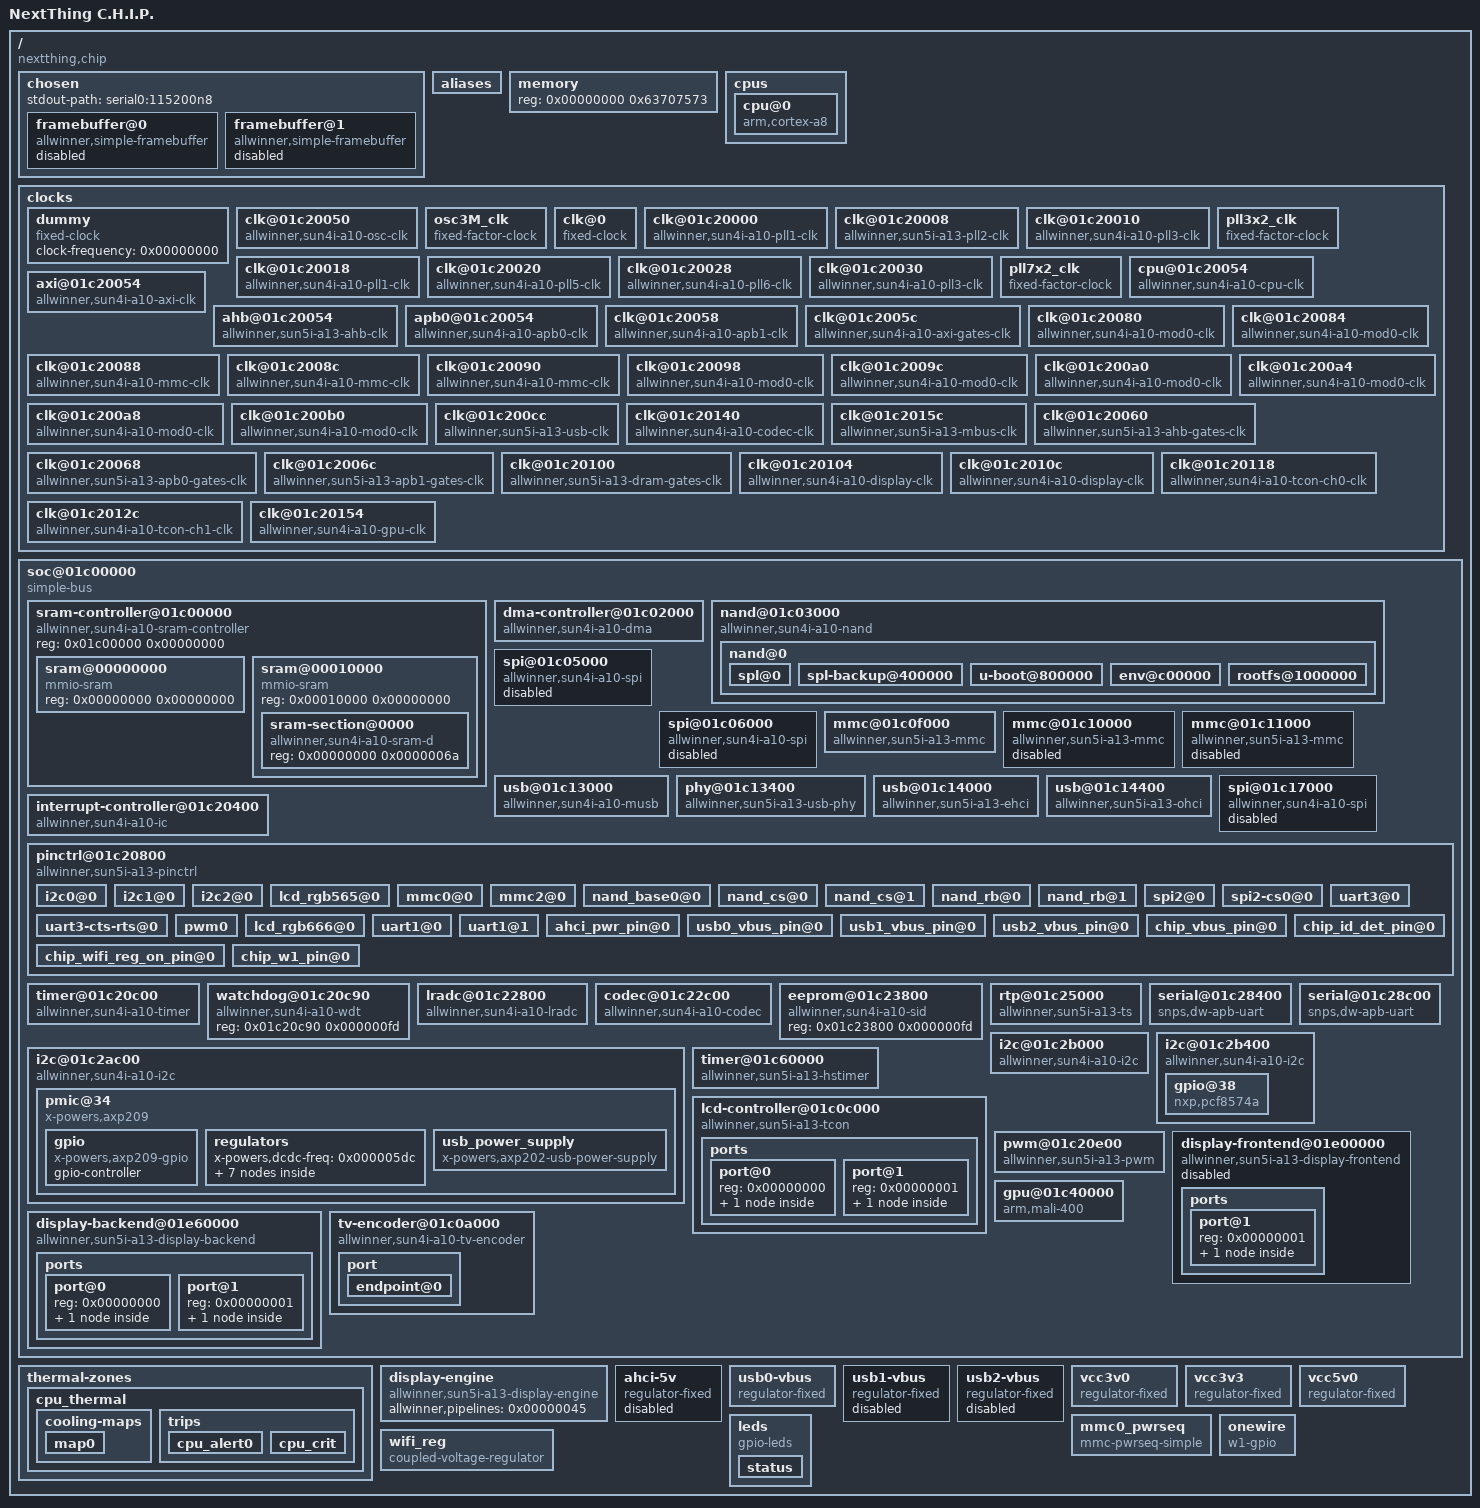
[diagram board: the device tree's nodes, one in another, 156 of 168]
/dts-v1/;
// magic:		0xd00dfeed
// totalsize:		0x9e24 (40484)
// off_dt_struct:	0x38
// off_dt_strings:	0x9414
// off_mem_rsvmap:	0x28
// version:		17
// last_comp_version:	16
// boot_cpuid_phys:	0x0
// size_dt_strings:	0xa10
// size_dt_struct:	0x93dc

/ {
    #address-cells = <0x00000001>;
    #size-cells = <0x00000001>;
    interrupt-parent = <0x00000001>;
    model = "NextThing C.H.I.P.";
    compatible = "nextthing,chip", "allwinner,sun5i-r8", "allwinner,sun5i-a13";
    chosen {
        #address-cells = <0x00000001>;
        #size-cells = <0x00000001>;
        ranges;
        stdout-path = "serial0:115200n8";
        framebuffer@0 {
            compatible = "allwinner,simple-framebuffer", "simple-framebuffer";
            allwinner,pipeline = "de_be0-lcd0";
            clocks = <0x00000002 0x00000003 0x00000003 0x626c6564 0x6672616d 0x00000003 0x696e6e65 0x6d656275>;
            status = "disabled";
        };
        framebuffer@1 {
            compatible = "allwinner,simple-framebuffer", "simple-framebuffer";
            allwinner,pipeline = "de_be0-lcd0-tve0";
            clocks = <0x00000002 0x00000002 0x00000005 0x0000006a 0x00000002 0x73657300 0x2f736f63 0x63403031 0x0000001b 0x30303030>;
            status = "disabled";
        };
    };
    aliases {
        i2c0 = "/soc@01c00000/i2c@01c2ac00";
        i2c1 = "/soc@01c00000/i2c@01c2b000";
        i2c2 = "/soc@01c00000/i2c@01c2b400";
        serial0 = "/soc@01c00000/serial@01c28400";
        serial1 = "/soc@01c00000/serial@01c28c00";
    };
    memory {
        device_type = "memory";
        reg = <0x00000000 0x63707573>;
    };
    cpus {
        #address-cells = <0x00000001>;
        #size-cells = <0x00000000>;
        cpu@0 {
            device_type = "cpu";
            compatible = "arm,cortex-a8";
            reg = <0x00000000>;
            clocks = <0x00000007>;
            clock-latency = <0x0003b9b0>;
            operating-points = <0x000f6180 0x000d2f00 0x0008ca00 0x00000003 0x00000003 0x00000003 0x00000003 0x00000003 0x00000003 0x00000002 0x6b730000 0x00000001>;
            #cooling-cells = <0x00000002>;
            cooling-min-level = <0x00000000>;
            cooling-max-level = <0x00000005>;
            cpu-supply = <0x00000008>;
            linux,phandle = <0x00000044>;
            phandle = <0x00000044>;
        };
    };
    clocks {
        #address-cells = <0x00000001>;
        #size-cells = <0x00000001>;
        ranges;
        dummy {
            #clock-cells = <0x00000000>;
            compatible = "fixed-clock";
            clock-frequency = <0x00000000>;
            linux,phandle = <0x0000000f>;
            phandle = <0x0000000f>;
        };
        clk@01c20050 {
            #clock-cells = <0x00000000>;
            compatible = "allwinner,sun4i-a10-osc-clk";
            reg = <0x01c20050 0x00000118>;
            clock-frequency = <0x016e3600>;
            clock-output-names = "osc24M";
            linux,phandle = <0x00000009>;
            phandle = <0x00000009>;
        };
        osc3M_clk {
            compatible = "fixed-factor-clock";
            #clock-cells = <0x00000000>;
            clock-div = <0x00000008>;
            clock-mult = <0x00000001>;
            clocks = <0x00000009>;
            clock-output-names = "osc3M";
            linux,phandle = <0x0000000a>;
            phandle = <0x0000000a>;
        };
        clk@0 {
            #clock-cells = <0x00000000>;
            compatible = "fixed-clock";
            clock-frequency = <0x00008000>;
            clock-output-names = "osc32k";
            linux,phandle = <0x0000000d>;
            phandle = <0x0000000d>;
        };
        clk@01c20000 {
            #clock-cells = <0x00000000>;
            compatible = "allwinner,sun4i-a10-pll1-clk";
            reg = <0x01c20000 0x00000063>;
            clocks = <0x00000009>;
            clock-output-names = "pll1";
            linux,phandle = <0x0000000e>;
            phandle = <0x0000000e>;
        };
        clk@01c20008 {
            #clock-cells = <0x00000001>;
            compatible = "allwinner,sun5i-a13-pll2-clk";
            reg = <0x01c20008 0x00000063>;
            clocks = <0x00000009>;
            clock-output-names = "pll2-1x", "pll2-2x", "pll2-4x", "pll2-8x";
            linux,phandle = <0x00000014>;
            phandle = <0x00000014>;
        };
        clk@01c20010 {
            #clock-cells = <0x00000000>;
            compatible = "allwinner,sun4i-a10-pll3-clk";
            reg = <0x01c20010 0x00000063>;
            clocks = <0x0000000a>;
            clock-output-names = "pll3";
            linux,phandle = <0x0000000b>;
            phandle = <0x0000000b>;
        };
        pll3x2_clk {
            compatible = "fixed-factor-clock";
            #clock-cells = <0x00000000>;
            clock-div = <0x00000001>;
            clock-mult = <0x00000002>;
            clocks = <0x0000000b>;
            clock-output-names = "pll3-2x";
            linux,phandle = <0x00000017>;
            phandle = <0x00000017>;
        };
        clk@01c20018 {
            #clock-cells = <0x00000000>;
            compatible = "allwinner,sun4i-a10-pll1-clk";
            reg = <0x01c20018 0x00000063>;
            clocks = <0x00000009>;
            clock-output-names = "pll4";
            linux,phandle = <0x00000019>;
            phandle = <0x00000019>;
        };
        clk@01c20020 {
            #clock-cells = <0x00000001>;
            compatible = "allwinner,sun4i-a10-pll5-clk";
            reg = <0x01c20020 0x00000063>;
            clocks = <0x00000009>;
            clock-output-names = "pll5_ddr", "pll5_other";
            linux,phandle = <0x00000013>;
            phandle = <0x00000013>;
        };
        clk@01c20028 {
            #clock-cells = <0x00000001>;
            compatible = "allwinner,sun4i-a10-pll6-clk";
            reg = <0x01c20028 0x00000063>;
            clocks = <0x00000009>;
            clock-output-names = "pll6_sata", "pll6_other", "pll6";
            linux,phandle = <0x00000011>;
            phandle = <0x00000011>;
        };
        clk@01c20030 {
            #clock-cells = <0x00000000>;
            compatible = "allwinner,sun4i-a10-pll3-clk";
            reg = <0x01c20030 0x00000063>;
            clocks = <0x0000000a>;
            clock-output-names = "pll7";
            linux,phandle = <0x0000000c>;
            phandle = <0x0000000c>;
        };
        pll7x2_clk {
            compatible = "fixed-factor-clock";
            #clock-cells = <0x00000000>;
            clock-div = <0x00000001>;
            clock-mult = <0x00000002>;
            clocks = <0x0000000c>;
            clock-output-names = "pll7-2x";
            linux,phandle = <0x00000018>;
            phandle = <0x00000018>;
        };
        cpu@01c20054 {
            #clock-cells = <0x00000000>;
            compatible = "allwinner,sun4i-a10-cpu-clk";
            reg = <0x01c20054 0x00000063>;
            clocks = <0x0000000d 0x00000003 0x00000003 0x00000003>;
            clock-output-names = "cpu";
            linux,phandle = <0x00000007>;
            phandle = <0x00000007>;
        };
        axi@01c20054 {
            #clock-cells = <0x00000000>;
            compatible = "allwinner,sun4i-a10-axi-clk";
            reg = <0x01c20054 0x00000063>;
            clocks = <0x00000007>;
            clock-output-names = "axi";
            linux,phandle = <0x00000010>;
            phandle = <0x00000010>;
        };
        ahb@01c20054 {
            #clock-cells = <0x00000000>;
            compatible = "allwinner,sun5i-a13-ahb-clk";
            reg = <0x01c20054 0x00000063>;
            clocks = <0x00000010 0x00000003 0x00000003 0x00000003>;
            clock-output-names = "ahb";
            assigned-clocks = <0x00000012>;
            assigned-clock-parents = <0x00000011 0x000000fd>;
            linux,phandle = <0x00000012>;
            phandle = <0x00000012>;
        };
        apb0@01c20054 {
            #clock-cells = <0x00000000>;
            compatible = "allwinner,sun4i-a10-apb0-clk";
            reg = <0x01c20054 0x00000063>;
            clocks = <0x00000012>;
            clock-output-names = "apb0";
            linux,phandle = <0x00000015>;
            phandle = <0x00000015>;
        };
        clk@01c20058 {
            #clock-cells = <0x00000000>;
            compatible = "allwinner,sun4i-a10-apb1-clk";
            reg = <0x01c20058 0x00000063>;
            clocks = <0x00000009 0x00000003 0x00000000 0x00000016>;
            clock-output-names = "apb1";
            linux,phandle = <0x00000016>;
            phandle = <0x00000016>;
        };
        clk@01c2005c {
            #clock-cells = <0x00000001>;
            compatible = "allwinner,sun4i-a10-axi-gates-clk";
            reg = <0x01c2005c 0x00000063>;
            clocks = <0x00000010>;
            clock-indices = <0x00000000>;
            clock-output-names = "axi_dram";
            linux,phandle = <0x0000004f>;
            phandle = <0x0000004f>;
        };
        clk@01c20080 {
            #clock-cells = <0x00000000>;
            compatible = "allwinner,sun4i-a10-mod0-clk";
            reg = <0x01c20080 0x00000063>;
            clocks = <0x00000009 0x00000001 0x6e616e64 0x000000fd 0x00000103>;
            clock-output-names = "nand";
            linux,phandle = <0x0000001a>;
            phandle = <0x0000001a>;
        };
        clk@01c20084 {
            #clock-cells = <0x00000000>;
            compatible = "allwinner,sun4i-a10-mod0-clk";
            reg = <0x01c20084 0x00000063>;
            clocks = <0x00000009 0x00000001 0x6d730000 0x00000050 0x00000050>;
            clock-output-names = "ms";
            linux,phandle = <0x00000050>;
            phandle = <0x00000050>;
        };
        clk@01c20088 {
            #clock-cells = <0x00000001>;
            compatible = "allwinner,sun4i-a10-mmc-clk";
            reg = <0x01c20088 0x00000063>;
            clocks = <0x00000009 0x00000001 0x6d6d6330 0x006d6d63 0x00000003>;
            clock-output-names = "mmc0", "mmc0_output", "mmc0_sample";
            linux,phandle = <0x00000021>;
            phandle = <0x00000021>;
        };
        clk@01c2008c {
            #clock-cells = <0x00000001>;
            compatible = "allwinner,sun4i-a10-mmc-clk";
            reg = <0x01c2008c 0x00000063>;
            clocks = <0x00000009 0x00000001 0x6d6d6331 0x006d6d63 0x00000003>;
            clock-output-names = "mmc1", "mmc1_output", "mmc1_sample";
            linux,phandle = <0x00000025>;
            phandle = <0x00000025>;
        };
        clk@01c20090 {
            #clock-cells = <0x00000001>;
            compatible = "allwinner,sun4i-a10-mmc-clk";
            reg = <0x01c20090 0x00000063>;
            clocks = <0x00000009 0x00000001 0x6d6d6332 0x006d6d63 0x00000003>;
            clock-output-names = "mmc2", "mmc2_output", "mmc2_sample";
            linux,phandle = <0x00000026>;
            phandle = <0x00000026>;
        };
        clk@01c20098 {
            #clock-cells = <0x00000000>;
            compatible = "allwinner,sun4i-a10-mod0-clk";
            reg = <0x01c20098 0x00000063>;
            clocks = <0x00000009 0x00000001 0x74730000 0x00000051 0x00000051>;
            clock-output-names = "ts";
            linux,phandle = <0x00000051>;
            phandle = <0x00000051>;
        };
        clk@01c2009c {
            #clock-cells = <0x00000000>;
            compatible = "allwinner,sun4i-a10-mod0-clk";
            reg = <0x01c2009c 0x00000063>;
            clocks = <0x00000009 0x00000001 0x73730000 0x00000052 0x00000052>;
            clock-output-names = "ss";
            linux,phandle = <0x00000052>;
            phandle = <0x00000052>;
        };
        clk@01c200a0 {
            #clock-cells = <0x00000000>;
            compatible = "allwinner,sun4i-a10-mod0-clk";
            reg = <0x01c200a0 0x00000063>;
            clocks = <0x00000009 0x00000001 0x73706930 0x000000fd 0x00000103>;
            clock-output-names = "spi0";
            linux,phandle = <0x0000001f>;
            phandle = <0x0000001f>;
        };
        clk@01c200a4 {
            #clock-cells = <0x00000000>;
            compatible = "allwinner,sun4i-a10-mod0-clk";
            reg = <0x01c200a4 0x00000063>;
            clocks = <0x00000009 0x00000001 0x73706931 0x000000fd 0x00000103>;
            clock-output-names = "spi1";
            linux,phandle = <0x00000020>;
            phandle = <0x00000020>;
        };
        clk@01c200a8 {
            #clock-cells = <0x00000000>;
            compatible = "allwinner,sun4i-a10-mod0-clk";
            reg = <0x01c200a8 0x00000063>;
            clocks = <0x00000009 0x00000001 0x73706932 0x000000fd 0x00000103>;
            clock-output-names = "spi2";
            linux,phandle = <0x0000002f>;
            phandle = <0x0000002f>;
        };
        clk@01c200b0 {
            #clock-cells = <0x00000000>;
            compatible = "allwinner,sun4i-a10-mod0-clk";
            reg = <0x01c200b0 0x00000063>;
            clocks = <0x00000009 0x00000001 0x69723000 0x00000053 0x00000053>;
            clock-output-names = "ir0";
            linux,phandle = <0x00000053>;
            phandle = <0x00000053>;
        };
        clk@01c200cc {
            #clock-cells = <0x00000001>;
            #reset-cells = <0x00000001>;
            compatible = "allwinner,sun5i-a13-usb-clk";
            reg = <0x01c200cc 0x00000063>;
            clocks = <0x00000011 0x00000128>;
            clock-output-names = "usb_ohci0", "usb_phy";
            linux,phandle = <0x00000029>;
            phandle = <0x00000029>;
        };
        clk@01c20140 {
            #clock-cells = <0x00000000>;
            compatible = "allwinner,sun4i-a10-codec-clk";
            reg = <0x01c20140 0x00000063>;
            clocks = <0x00000014 0x00000128>;
            clock-output-names = "codec";
            linux,phandle = <0x00000032>;
            phandle = <0x00000032>;
        };
        clk@01c2015c {
            #clock-cells = <0x00000000>;
            compatible = "allwinner,sun5i-a13-mbus-clk";
            reg = <0x01c2015c 0x00000063>;
            clocks = <0x00000009 0x00000001 0x6d627573 0x000000fd 0x00000103>;
            clock-output-names = "mbus";
            linux,phandle = <0x00000054>;
            phandle = <0x00000054>;
        };
        clk@01c20060 {
            #clock-cells = <0x00000001>;
            compatible = "allwinner,sun5i-a13-ahb-gates-clk";
            reg = <0x01c20060 0x00000063>;
            clocks = <0x00000012>;
            clock-indices = <0x00000000 0x00000006 0x0000000a 0x00000015 0x00000022 0x0000002e 0x000000d0 0x74670061 0x6f686369 0x646d6100 0x5f6d6d63 0x68625f6d 0x00616862 0x70693000 0x5f737069 0x00616862 0x6168625f 0x6168625f 0x5f666500 0x6d616c69 0x000000fd 0x00000103 0x636c6b40>;
            clock-output-names = "ahb_usbotg", "ahb_ehci", "ahb_ohci", "ahb_ss", "ahb_dma", "ahb_bist", "ahb_mmc0", "ahb_mmc1", "ahb_mmc2", "ahb_nand", "ahb_sdram", "ahb_spi0", "ahb_spi1", "ahb_spi2", "ahb_stimer", "ahb_ve", "ahb_tve", "ahb_lcd", "ahb_csi", "ahb_de_be", "ahb_de_fe", "ahb_iep", "ahb_mali400";
            linux,phandle = <0x00000002>;
            phandle = <0x00000002>;
        };
        clk@01c20068 {
            #clock-cells = <0x00000001>;
            compatible = "allwinner,sun5i-a13-apb0-gates-clk";
            reg = <0x01c20068 0x00000063>;
            clocks = <0x00000015>;
            clock-indices = <0x00000000 0x0000001c 0x65630061>;
            clock-output-names = "apb0_codec", "apb0_pio", "apb0_ir";
            linux,phandle = <0x00000030>;
            phandle = <0x00000030>;
        };
        clk@01c2006c {
            #clock-cells = <0x00000001>;
            compatible = "allwinner,sun5i-a13-apb1-gates-clk";
            reg = <0x01c2006c 0x00000063>;
            clocks = <0x00000016>;
            clock-indices = <0x00000000 0x00000013 0x61706231 0x32633100 0x62315f75>;
            clock-output-names = "apb1_i2c0", "apb1_i2c1", "apb1_i2c2", "apb1_uart1", "apb1_uart3";
            linux,phandle = <0x00000033>;
            phandle = <0x00000033>;
        };
        clk@01c20100 {
            #clock-cells = <0x00000001>;
            compatible = "allwinner,sun5i-a13-dram-gates-clk", "allwinner,sun4i-a10-gates-clk";
            reg = <0x01c20100 0x00000063>;
            clocks = <0x00000013 0x00000177>;
            clock-indices = <0x00000000 0x0000001d 0x00000128 0x5f637369 0x6472616d 0x61636500>;
            clock-output-names = "dram_ve", "dram_csi", "dram_de_fe", "dram_de_be", "dram_ace", "dram_iep";
            linux,phandle = <0x00000005>;
            phandle = <0x00000005>;
        };
        clk@01c20104 {
            #clock-cells = <0x00000000>;
            #reset-cells = <0x00000000>;
            compatible = "allwinner,sun4i-a10-display-clk";
            reg = <0x01c20104 0x00000063>;
            clocks = <0x0000000b 0x00000003 0x65000000 0x00000003>;
            clock-output-names = "de-be";
            linux,phandle = <0x00000003>;
            phandle = <0x00000003>;
        };
        clk@01c2010c {
            #clock-cells = <0x00000000>;
            #reset-cells = <0x00000000>;
            compatible = "allwinner,sun4i-a10-display-clk";
            reg = <0x01c2010c 0x00000063>;
            clocks = <0x0000000b 0x00000003 0x65000000 0x0000003c>;
            clock-output-names = "de-fe";
            linux,phandle = <0x0000003c>;
            phandle = <0x0000003c>;
        };
        clk@01c20118 {
            #clock-cells = <0x00000000>;
            #reset-cells = <0x00000001>;
            compatible = "allwinner,sun4i-a10-tcon-ch0-clk";
            reg = <0x01c20118 0x00000063>;
            clocks = <0x0000000b 0x00000003 0x2d636830 0x00000004>;
            clock-output-names = "tcon-ch0-sclk";
            linux,phandle = <0x00000004>;
            phandle = <0x00000004>;
        };
        clk@01c2012c {
            #clock-cells = <0x00000000>;
            compatible = "allwinner,sun4i-a10-tcon-ch1-clk";
            reg = <0x01c2012c 0x00000063>;
            clocks = <0x0000000b 0x00000003 0x2d636831 0x00000004>;
            clock-output-names = "tcon-ch1-sclk";
            linux,phandle = <0x00000006>;
            phandle = <0x00000006>;
        };
        clk@01c20154 {
            #clock-cells = <0x00000000>;
            #reset-cells = <0x00000000>;
            compatible = "allwinner,sun4i-a10-gpu-clk";
            reg = <0x01c20154 0x00000063>;
            clocks = <0x0000000b 0x0000000c 0x00000128 0x00000004 0x00000004 0x00000002>;
            clock-output-names = "mali";
            linux,phandle = <0x00000041>;
            phandle = <0x00000041>;
        };
    };
    soc@01c00000 {
        compatible = "simple-bus";
        #address-cells = <0x00000001>;
        #size-cells = <0x00000001>;
        ranges;
        sram-controller@01c00000 {
            compatible = "allwinner,sun4i-a10-sram-controller";
            reg = <0x01c00000 0x00000000>;
            #address-cells = <0x00000001>;
            #size-cells = <0x00000001>;
            ranges;
            sram@00000000 {
                compatible = "mmio-sram";
                reg = <0x00000000 0x00000000>;
                #address-cells = <0x00000001>;
                #size-cells = <0x00000001>;
                ranges = <0x00000000 0x00000004 0x00000004>;
                linux,phandle = <0x00000055>;
                phandle = <0x00000055>;
            };
            sram@00010000 {
                compatible = "mmio-sram";
                reg = <0x00010000 0x00000000>;
                #address-cells = <0x00000001>;
                #size-cells = <0x00000001>;
                ranges = <0x00000000 0x00000004 0x00000004>;
                linux,phandle = <0x00000056>;
                phandle = <0x00000056>;
                sram-section@0000 {
                    compatible = "allwinner,sun4i-a10-sram-d";
                    reg = <0x00000000 0x0000006a>;
                    status = "okay";
                    linux,phandle = <0x00000028>;
                    phandle = <0x00000028>;
                };
            };
        };
        dma-controller@01c02000 {
            compatible = "allwinner,sun4i-a10-dma";
            reg = <0x01c02000 0x00000192>;
            interrupts = <0x0000001b>;
            clocks = <0x00000002 0x0000019d>;
            #dma-cells = <0x00000002>;
            linux,phandle = <0x0000001e>;
            phandle = <0x0000001e>;
        };
        nand@01c03000 {
            compatible = "allwinner,sun4i-a10-nand";
            reg = <0x01c03000 0x00000192>;
            interrupts = <0x00000025>;
            clocks = <0x00000002 0x00000008 0x00000003>;
            clock-names = "ahb", "mod";
            #address-cells = <0x00000001>;
            #size-cells = <0x00000000>;
            status = "okay";
            pinctrl-names = "default";
            pinctrl-0 = <0x0000001b 0x0000000c 0x00000003>;
            dmas = <0x0000001e 0x00000005 0x00000003>;
            dma-names = "rxtx";
            linux,phandle = <0x00000057>;
            phandle = <0x00000057>;
            nand@0 {
                #address-cells = <0x00000002>;
                #size-cells = <0x00000002>;
                reg = <0x00000000>;
                allwinner,rb = <0x00000000>;
                nand-ecc-mode = "hw";
                spl@0 {
                    label = "SPL";
                    reg = <0x00000000 0x00000002 0x75704034 0x0000000b>;
                };
                spl-backup@400000 {
                    label = "SPL.backup";
                    reg = <0x00000000 0x00000002 0x30303030 0x000001f6>;
                };
                u-boot@800000 {
                    label = "U-Boot";
                    reg = <0x00000000 0x00000002 0x30300000 0x656e7600>;
                };
                env@c00000 {
                    label = "env";
                    reg = <0x00000000 0x00000002 0x30303030 0x000001f6>;
                };
                rootfs@1000000 {
                    label = "rootfs";
                    reg = <0x00000000 0x00000002 0x73706940 0x00000003>;
                };
            };
        };
        spi@01c05000 {
            compatible = "allwinner,sun4i-a10-spi";
            reg = <0x01c05000 0x00000192>;
            interrupts = <0x0000000a>;
            clocks = <0x00000002 0x00000008 0x00000003>;
            clock-names = "ahb", "mod";
            dmas = <0x0000001e 0x00000001 0x000001d1 0x00000009 0x00000000 0x00000001>;
            dma-names = "rx", "tx";
            status = "disabled";
            #address-cells = <0x00000001>;
            #size-cells = <0x00000000>;
            linux,phandle = <0x00000058>;
            phandle = <0x00000058>;
        };
        spi@01c06000 {
            compatible = "allwinner,sun4i-a10-spi";
            reg = <0x01c06000 0x00000192>;
            interrupts = <0x0000000b>;
            clocks = <0x00000002 0x00000008 0x00000003>;
            clock-names = "ahb", "mod";
            dmas = <0x0000001e 0x00000001 0x000001d1 0x00000009 0x00000000 0x00000001>;
            dma-names = "rx", "tx";
            status = "disabled";
            #address-cells = <0x00000001>;
            #size-cells = <0x00000000>;
            linux,phandle = <0x00000059>;
            phandle = <0x00000059>;
        };
        mmc@01c0f000 {
            compatible = "allwinner,sun5i-a13-mmc";
            reg = <0x01c0f000 0x00000063>;
            clocks = <0x00000002 0x00000021 0x00000003 0x6d6d6300 0x65000000 0x00000020 0x6f6b6179 0x00000000>;
            clock-names = "ahb", "mmc", "output", "sample";
            interrupts = <0x00000020>;
            status = "okay";
            #address-cells = <0x00000001>;
            #size-cells = <0x00000000>;
            pinctrl-names = "default";
            pinctrl-0 = <0x00000022>;
            vmmc-supply = <0x00000023>;
            mmc-pwrseq = <0x00000024>;
            bus-width = <0x00000004>;
            non-removable;
            linux,phandle = <0x0000005a>;
            phandle = <0x0000005a>;
        };
        mmc@01c10000 {
            compatible = "allwinner,sun5i-a13-mmc";
            reg = <0x01c10000 0x00000063>;
            clocks = <0x00000002 0x00000025 0x00000003 0x6d6d6300 0x65000000 0x00000021 0x64697361 0x00000004>;
            clock-names = "ahb", "mmc", "output", "sample";
            interrupts = <0x00000021>;
            status = "disabled";
            #address-cells = <0x00000001>;
            #size-cells = <0x00000000>;
            linux,phandle = <0x0000005b>;
            phandle = <0x0000005b>;
        };
        mmc@01c11000 {
            compatible = "allwinner,sun5i-a13-mmc";
            reg = <0x01c11000 0x00000063>;
            clocks = <0x00000002 0x00000026 0x00000003 0x6d6d6300 0x65000000 0x00000022 0x64697361 0x00000004>;
            clock-names = "ahb", "mmc", "output", "sample";
            interrupts = <0x00000022>;
            status = "disabled";
            #address-cells = <0x00000001>;
            #size-cells = <0x00000000>;
            linux,phandle = <0x0000005c>;
            phandle = <0x0000005c>;
        };
        usb@01c13000 {
            compatible = "allwinner,sun4i-a10-musb";
            reg = <0x01c13000 0x00000063>;
            clocks = <0x00000002 0x00000192>;
            interrupts = <0x00000026>;
            interrupt-names = "mc";
            phys = <0x00000027 0x00000240>;
            phy-names = "usb";
            extcon = <0x00000027 0x00000251>;
            allwinner,sram = <0x00000028 0x0000006a>;
            status = "okay";
            dr_mode = "otg";
            linux,phandle = <0x0000005d>;
            phandle = <0x0000005d>;
        };
        phy@01c13400 {
            #phy-cells = <0x00000001>;
            compatible = "allwinner,sun5i-a13-usb-phy";
            reg = <0x01c13400 0x00000003 0x6374726c 0x00000008>;
            reg-names = "phy_ctrl", "pmu1";
            clocks = <0x00000029 0x000001a8>;
            clock-names = "usb_phy";
            resets = <0x00000029 0x00000003 0x5f726573 0x74000000>;
            reset-names = "usb0_reset", "usb1_reset";
            status = "okay";
            pinctrl-names = "default";
            pinctrl-0 = <0x0000002a>;
            usb0_id_det-gpio = <0x0000002b 0x00000003 0x00000003 0x00000003>;
            usb0_vbus_power-supply = <0x0000002c>;
            usb0_vbus-supply = <0x0000002d>;
            usb1_vbus-supply = <0x0000002e>;
            linux,phandle = <0x00000027>;
            phandle = <0x00000027>;
        };
        usb@01c14000 {
            compatible = "allwinner,sun5i-a13-ehci", "generic-ehci";
            reg = <0x01c14000 0x00000192>;
            interrupts = <0x00000027>;
            clocks = <0x00000002 0x0000023b>;
            phys = <0x00000027 0x00000240>;
            phy-names = "usb";
            status = "okay";
            linux,phandle = <0x0000005e>;
            phandle = <0x0000005e>;
        };
        usb@01c14400 {
            compatible = "allwinner,sun5i-a13-ohci", "generic-ohci";
            reg = <0x01c14400 0x00000192>;
            interrupts = <0x00000028>;
            clocks = <0x00000029 0x00000003 0x00000001 0x75736200>;
            phys = <0x00000027 0x00000240>;
            phy-names = "usb";
            status = "okay";
            linux,phandle = <0x0000005f>;
            phandle = <0x0000005f>;
        };
        spi@01c17000 {
            compatible = "allwinner,sun4i-a10-spi";
            reg = <0x01c17000 0x00000192>;
            interrupts = <0x0000000c>;
            clocks = <0x00000002 0x00000008 0x00000003>;
            clock-names = "ahb", "mod";
            dmas = <0x0000001e 0x00000001 0x000001d1 0x00000009 0x00000000 0x00000001>;
            dma-names = "rx", "tx";
            status = "disabled";
            #address-cells = <0x00000001>;
            #size-cells = <0x00000000>;
            linux,phandle = <0x00000060>;
            phandle = <0x00000060>;
        };
        interrupt-controller@01c20400 {
            compatible = "allwinner,sun4i-a10-ic";
            reg = <0x01c20400 0x000002da>;
            interrupt-controller;
            #interrupt-cells = <0x00000001>;
            linux,phandle = <0x00000001>;
            phandle = <0x00000001>;
        };
        pinctrl@01c20800 {
            reg = <0x01c20800 0x00000192>;
            interrupts = <0x0000001c>;
            clocks = <0x00000030 0x00000300>;
            gpio-controller;
            interrupt-controller;
            #interrupt-cells = <0x00000003>;
            #gpio-cells = <0x00000003>;
            compatible = "allwinner,sun5i-a13-pinctrl";
            linux,phandle = <0x0000002b>;
            phandle = <0x0000002b>;
            i2c0@0 {
                allwinner,pins = "PB0", "PB1";
                allwinner,function = "i2c0";
                allwinner,drive = <0x00000000>;
                allwinner,pull = <0x00000000>;
                linux,phandle = <0x00000037>;
                phandle = <0x00000037>;
            };
            i2c1@0 {
                allwinner,pins = "PB15", "PB16";
                allwinner,function = "i2c1";
                allwinner,drive = <0x00000000>;
                allwinner,pull = <0x00000000>;
                linux,phandle = <0x00000038>;
                phandle = <0x00000038>;
            };
            i2c2@0 {
                allwinner,pins = "PB17", "PB18";
                allwinner,function = "i2c2";
                allwinner,drive = <0x00000000>;
                allwinner,pull = <0x00000000>;
                linux,phandle = <0x00000039>;
                phandle = <0x00000039>;
            };
            lcd_rgb565@0 {
                allwinner,pins = "PD3", "PD4", "PD5", "PD6", "PD7", "PD10", "PD11", "PD12", "PD13", "PD14", "PD15", "PD19", "PD20", "PD21", "PD22", "PD23", "PD24", "PD25", "PD26", "PD27";
                allwinner,function = "lcd0";
                allwinner,drive = <0x00000000>;
                allwinner,pull = <0x00000000>;
                linux,phandle = <0x00000061>;
                phandle = <0x00000061>;
            };
            mmc0@0 {
                allwinner,pins = "PF0", "PF1", "PF2", "PF3", "PF4", "PF5";
                allwinner,function = "mmc0";
                allwinner,drive = <0x00000002>;
                allwinner,pull = <0x00000001>;
                linux,phandle = <0x00000022>;
                phandle = <0x00000022>;
            };
            mmc2@0 {
                allwinner,pins = "PC6", "PC7", "PC8", "PC9", "PC10", "PC11", "PC12", "PC13", "PC14", "PC15";
                allwinner,function = "mmc2";
                allwinner,drive = <0x00000002>;
                allwinner,pull = <0x00000001>;
                linux,phandle = <0x00000062>;
                phandle = <0x00000062>;
            };
            nand_base0@0 {
                allwinner,pins = "PC0", "PC1", "PC2", "PC5", "PC8", "PC9", "PC10", "PC11", "PC12", "PC13", "PC14", "PC15";
                allwinner,function = "nand0";
                allwinner,drive = <0x00000000>;
                allwinner,pull = <0x00000000>;
                linux,phandle = <0x0000001b>;
                phandle = <0x0000001b>;
            };
            nand_cs@0 {
                allwinner,pins = "PC4";
                allwinner,function = "nand0";
                allwinner,drive = <0x00000000>;
                allwinner,pull = <0x00000000>;
                linux,phandle = <0x0000001c>;
                phandle = <0x0000001c>;
            };
            nand_cs@1 {
                allwinner,pins = "PC3";
                allwinner,function = "nand0";
                allwinner,drive = <0x00000000>;
                allwinner,pull = <0x00000000>;
                linux,phandle = <0x00000063>;
                phandle = <0x00000063>;
            };
            nand_rb@0 {
                allwinner,pins = "PC6";
                allwinner,function = "nand0";
                allwinner,drive = <0x00000000>;
                allwinner,pull = <0x00000000>;
                linux,phandle = <0x0000001d>;
                phandle = <0x0000001d>;
            };
            nand_rb@1 {
                allwinner,pins = "PC7";
                allwinner,function = "nand0";
                allwinner,drive = <0x00000000>;
                allwinner,pull = <0x00000000>;
                linux,phandle = <0x00000064>;
                phandle = <0x00000064>;
            };
            spi2@0 {
                allwinner,pins = "PE1", "PE2", "PE3";
                allwinner,function = "spi2";
                allwinner,drive = <0x00000000>;
                allwinner,pull = <0x00000000>;
                linux,phandle = <0x00000065>;
                phandle = <0x00000065>;
            };
            spi2-cs0@0 {
                allwinner,pins = "PE0";
                allwinner,function = "spi2";
                allwinner,drive = <0x00000000>;
                allwinner,pull = <0x00000000>;
                linux,phandle = <0x00000066>;
                phandle = <0x00000066>;
            };
            uart3@0 {
                allwinner,pins = "PG9", "PG10";
                allwinner,function = "uart3";
                allwinner,drive = <0x00000000>;
                allwinner,pull = <0x00000000>;
                linux,phandle = <0x00000035>;
                phandle = <0x00000035>;
            };
            uart3-cts-rts@0 {
                allwinner,pins = "PG11", "PG12";
                allwinner,function = "uart3";
                allwinner,drive = <0x00000000>;
                allwinner,pull = <0x00000000>;
                linux,phandle = <0x00000036>;
                phandle = <0x00000036>;
            };
            pwm0 {
                allwinner,pins = "PB2";
                allwinner,function = "pwm";
                allwinner,drive = <0x00000000>;
                allwinner,pull = <0x00000000>;
                linux,phandle = <0x00000067>;
                phandle = <0x00000067>;
            };
            lcd_rgb666@0 {
                allwinner,pins = "PD2", "PD3", "PD4", "PD5", "PD6", "PD7", "PD10", "PD11", "PD12", "PD13", "PD14", "PD15", "PD18", "PD19", "PD20", "PD21", "PD22", "PD23", "PD24", "PD25", "PD26", "PD27";
                allwinner,function = "lcd0";
                allwinner,drive = <0x00000000>;
                allwinner,pull = <0x00000000>;
                linux,phandle = <0x00000068>;
                phandle = <0x00000068>;
            };
            uart1@0 {
                allwinner,pins = "PE10", "PE11";
                allwinner,function = "uart1";
                allwinner,drive = <0x00000000>;
                allwinner,pull = <0x00000000>;
                linux,phandle = <0x00000069>;
                phandle = <0x00000069>;
            };
            uart1@1 {
                allwinner,pins = "PG3", "PG4";
                allwinner,function = "uart1";
                allwinner,drive = <0x00000000>;
                allwinner,pull = <0x00000000>;
                linux,phandle = <0x00000034>;
                phandle = <0x00000034>;
            };
            ahci_pwr_pin@0 {
                allwinner,pins = "PB8";
                allwinner,function = "gpio_out";
                allwinner,drive = <0x00000000>;
                allwinner,pull = <0x00000000>;
                linux,phandle = <0x00000046>;
                phandle = <0x00000046>;
            };
            usb0_vbus_pin@0 {
                allwinner,pins = "PB9";
                allwinner,function = "gpio_out";
                allwinner,drive = <0x00000000>;
                allwinner,pull = <0x00000000>;
                linux,phandle = <0x0000006a>;
                phandle = <0x0000006a>;
            };
            usb1_vbus_pin@0 {
                allwinner,pins = "PH6";
                allwinner,function = "gpio_out";
                allwinner,drive = <0x00000000>;
                allwinner,pull = <0x00000000>;
                linux,phandle = <0x00000048>;
                phandle = <0x00000048>;
            };
            usb2_vbus_pin@0 {
                allwinner,pins = "PH3";
                allwinner,function = "gpio_out";
                allwinner,drive = <0x00000000>;
                allwinner,pull = <0x00000000>;
                linux,phandle = <0x00000049>;
                phandle = <0x00000049>;
            };
            chip_vbus_pin@0 {
                allwinner,pins = "PB10";
                allwinner,function = "gpio_out";
                allwinner,drive = <0x00000000>;
                allwinner,pull = <0x00000000>;
                linux,phandle = <0x00000047>;
                phandle = <0x00000047>;
            };
            chip_wifi_reg_on_pin@0 {
                allwinner,pins = "PC19";
                allwinner,function = "gpio_out";
                allwinner,drive = <0x00000000>;
                allwinner,pull = <0x00000000>;
                linux,phandle = <0x0000004b>;
                phandle = <0x0000004b>;
            };
            chip_id_det_pin@0 {
                allwinner,pins = "PG2";
                allwinner,function = "gpio_in";
                allwinner,drive = <0x00000000>;
                allwinner,pull = <0x00000000>;
                linux,phandle = <0x0000002a>;
                phandle = <0x0000002a>;
            };
            chip_w1_pin@0 {
                allwinner,pins = "PD2";
                allwinner,function = "gpio_in";
                allwinner,drive = <0x00000000>;
                allwinner,pull = <0x00000001>;
                linux,phandle = <0x0000004c>;
                phandle = <0x0000004c>;
            };
        };
        timer@01c20c00 {
            compatible = "allwinner,sun4i-a10-timer";
            reg = <0x01c20c00 0x00000192>;
            interrupts = <0x00000016>;
            clocks = <0x00000009>;
        };
        watchdog@01c20c90 {
            compatible = "allwinner,sun4i-a10-wdt";
            reg = <0x01c20c90 0x000000fd>;
            linux,phandle = <0x0000006b>;
            phandle = <0x0000006b>;
        };
        lradc@01c22800 {
            #io-channel-cells = <0x00000001>;
            compatible = "allwinner,sun4i-a10-lradc";
            reg = <0x01c22800 0x00000192>;
            interrupts = <0x0000001f>;
            status = "okay";
            vref-supply = <0x00000031>;
            linux,phandle = <0x0000006c>;
            phandle = <0x0000006c>;
        };
        codec@01c22c00 {
            #sound-dai-cells = <0x00000000>;
            compatible = "allwinner,sun4i-a10-codec";
            reg = <0x01c22c00 0x00000192>;
            interrupts = <0x0000001e>;
            clocks = <0x00000030 0x0000000a 0x63000000>;
            clock-names = "apb", "codec";
            dmas = <0x0000001e 0x00000000 0x000001d1 0x00000005 0x00000003 0x00000003>;
            dma-names = "rx", "tx";
            status = "okay";
            linux,phandle = <0x0000006d>;
            phandle = <0x0000006d>;
        };
        eeprom@01c23800 {
            compatible = "allwinner,sun4i-a10-sid";
            reg = <0x01c23800 0x000000fd>;
            linux,phandle = <0x0000006e>;
            phandle = <0x0000006e>;
        };
        rtp@01c25000 {
            compatible = "allwinner,sun5i-a13-ts";
            reg = <0x01c25000 0x00000192>;
            interrupts = <0x0000001d>;
            #thermal-sensor-cells = <0x00000000>;
            linux,phandle = <0x00000042>;
            phandle = <0x00000042>;
        };
        serial@01c28400 {
            compatible = "snps,dw-apb-uart";
            reg = <0x01c28400 0x00000192>;
            interrupts = <0x00000002>;
            reg-shift = <0x00000002>;
            reg-io-width = <0x00000004>;
            clocks = <0x00000033 0x0000006a>;
            status = "okay";
            pinctrl-names = "default";
            pinctrl-0 = <0x00000034>;
            linux,phandle = <0x0000006f>;
            phandle = <0x0000006f>;
        };
        serial@01c28c00 {
            compatible = "snps,dw-apb-uart";
            reg = <0x01c28c00 0x00000192>;
            interrupts = <0x00000004>;
            reg-shift = <0x00000002>;
            reg-io-width = <0x00000004>;
            clocks = <0x00000033 0x0000006a>;
            status = "okay";
            pinctrl-names = "default";
            pinctrl-0 = <0x00000035 0x000000fd>;
            linux,phandle = <0x00000070>;
            phandle = <0x00000070>;
        };
        i2c@01c2ac00 {
            compatible = "allwinner,sun4i-a10-i2c";
            reg = <0x01c2ac00 0x00000192>;
            interrupts = <0x00000007>;
            clocks = <0x00000033 0x0000006a>;
            status = "okay";
            #address-cells = <0x00000001>;
            #size-cells = <0x00000000>;
            pinctrl-names = "default";
            pinctrl-0 = <0x00000037>;
            linux,phandle = <0x00000071>;
            phandle = <0x00000071>;
            pmic@34 {
                reg = <0x00000034>;
                interrupts = <0x00000000>;
                compatible = "x-powers,axp209";
                interrupt-controller;
                #interrupt-cells = <0x00000001>;
                linux,phandle = <0x00000072>;
                phandle = <0x00000072>;
                gpio {
                    compatible = "x-powers,axp209-gpio";
                    gpio-controller;
                    #gpio-cells = <0x00000002>;
                    linux,phandle = <0x0000004a>;
                    phandle = <0x0000004a>;
                };
                regulators {
                    x-powers,dcdc-freq = <0x000005dc>;
                    dcdc2 {
                        regulator-name = "cpuvdd";
                        regulator-min-microvolt = <0x000f4240>;
                        regulator-max-microvolt = <0x00155cc0>;
                        regulator-always-on;
                        linux,phandle = <0x00000008>;
                        phandle = <0x00000008>;
                    };
                    dcdc3 {
                        regulator-name = "corevdd";
                        regulator-min-microvolt = <0x000f4240>;
                        regulator-max-microvolt = <0x0013d620>;
                        regulator-always-on;
                        linux,phandle = <0x00000073>;
                        phandle = <0x00000073>;
                    };
                    ldo1 {
                        regulator-always-on;
                        regulator-min-microvolt = <0x0013d620>;
                        regulator-max-microvolt = <0x0013d620>;
                        regulator-name = "rtcvdd";
                        linux,phandle = <0x00000074>;
                        phandle = <0x00000074>;
                    };
                    ldo2 {
                        regulator-name = "avcc";
                        regulator-min-microvolt = <0x002932e0>;
                        regulator-max-microvolt = <0x00325aa0>;
                        regulator-always-on;
                        linux,phandle = <0x00000075>;
                        phandle = <0x00000075>;
                    };
                    ldo3 {
                        regulator-name = "vcc-wifi-1";
                        regulator-min-microvolt = <0x00325aa0>;
                        regulator-max-microvolt = <0x00325aa0>;
                        linux,phandle = <0x0000004d>;
                        phandle = <0x0000004d>;
                    };
                    ldo4 {
                        regulator-name = "vcc-wifi-2";
                        regulator-min-microvolt = <0x00325aa0>;
                        regulator-max-microvolt = <0x00325aa0>;
                        linux,phandle = <0x0000004e>;
                        phandle = <0x0000004e>;
                    };
                    ldo5 {
                        regulator-name = "vcc-1v8";
                        regulator-min-microvolt = <0x001b7740>;
                        regulator-max-microvolt = <0x001b7740>;
                        linux,phandle = <0x00000076>;
                        phandle = <0x00000076>;
                    };
                };
                usb_power_supply {
                    compatible = "x-powers,axp202-usb-power-supply";
                    status = "okay";
                    linux,phandle = <0x0000002c>;
                    phandle = <0x0000002c>;
                };
            };
        };
        i2c@01c2b000 {
            compatible = "allwinner,sun4i-a10-i2c";
            reg = <0x01c2b000 0x00000192>;
            interrupts = <0x00000008>;
            clocks = <0x00000033 0x0000006a>;
            status = "okay";
            #address-cells = <0x00000001>;
            #size-cells = <0x00000000>;
            pinctrl-names = "default";
            pinctrl-0 = <0x00000038>;
            linux,phandle = <0x00000077>;
            phandle = <0x00000077>;
        };
        i2c@01c2b400 {
            compatible = "allwinner,sun4i-a10-i2c";
            reg = <0x01c2b400 0x00000192>;
            interrupts = <0x00000009>;
            clocks = <0x00000033 0x0000006a>;
            status = "okay";
            #address-cells = <0x00000001>;
            #size-cells = <0x00000000>;
            pinctrl-names = "default";
            pinctrl-0 = <0x00000039>;
            linux,phandle = <0x00000078>;
            phandle = <0x00000078>;
            gpio@38 {
                compatible = "nxp,pcf8574a";
                reg = <0x00000038>;
                gpio-controller;
                #gpio-cells = <0x00000002>;
                interrupt-parent = <0x0000002b>;
                interrupts = <0x00000006 0x00000000 0x000002ef>;
                interrupt-controller;
                #interrupt-cells = <0x00000002>;
                linux,phandle = <0x00000079>;
                phandle = <0x00000079>;
            };
        };
        timer@01c60000 {
            compatible = "allwinner,sun5i-a13-hstimer";
            reg = <0x01c60000 0x00000192>;
            interrupts = <0x00000052 0x00000063>;
            clocks = <0x00000002 0x6c63642d>;
        };
        lcd-controller@01c0c000 {
            compatible = "allwinner,sun5i-a13-tcon";
            reg = <0x01c0c000 0x00000192>;
            interrupts = <0x0000002c>;
            resets = <0x00000004 0x00000284>;
            reset-names = "lcd";
            clocks = <0x00000002 0x00000003 0x74636f6e 0x31000000>;
            clock-names = "ahb", "tcon-ch0", "tcon-ch1";
            clock-output-names = "tcon-pixel-clock";
            status = "okay";
            linux,phandle = <0x0000007a>;
            phandle = <0x0000007a>;
            ports {
                #address-cells = <0x00000001>;
                #size-cells = <0x00000000>;
                port@0 {
                    #address-cells = <0x00000001>;
                    #size-cells = <0x00000000>;
                    reg = <0x00000000>;
                    linux,phandle = <0x0000007b>;
                    phandle = <0x0000007b>;
                    endpoint@0 {
                        reg = <0x00000000>;
                        remote-endpoint = <0x0000003a>;
                        linux,phandle = <0x0000003f>;
                        phandle = <0x0000003f>;
                    };
                };
                port@1 {
                    #address-cells = <0x00000001>;
                    #size-cells = <0x00000000>;
                    reg = <0x00000001>;
                    linux,phandle = <0x0000007c>;
                    phandle = <0x0000007c>;
                    endpoint@1 {
                        reg = <0x00000001>;
                        remote-endpoint = <0x0000003b>;
                        linux,phandle = <0x00000040>;
                        phandle = <0x00000040>;
                    };
                };
            };
        };
        pwm@01c20e00 {
            pinctrl-0 = <0x00000067>;
            pinctrl-names = "default";
            compatible = "allwinner,sun5i-a13-pwm";
            reg = <0x01c20e00 0x00000063>;
            clocks = <0x00000009>;
            #pwm-cells = <0x00000003>;
            status = "okay";
            linux,phandle = <0x0000007d>;
            phandle = <0x0000007d>;
        };
        display-frontend@01e00000 {
            compatible = "allwinner,sun5i-a13-display-frontend";
            reg = <0x01e00000 0x00000192>;
            interrupts = <0x0000002f>;
            clocks = <0x00000002 0x00000019 0x61686200 0x00000004 0x00000009>;
            clock-names = "ahb", "mod", "ram";
            resets = <0x0000003c>;
            status = "disabled";
            linux,phandle = <0x00000045>;
            phandle = <0x00000045>;
            ports {
                #address-cells = <0x00000001>;
                #size-cells = <0x00000000>;
                port@1 {
                    #address-cells = <0x00000001>;
                    #size-cells = <0x00000000>;
                    reg = <0x00000001>;
                    linux,phandle = <0x0000007e>;
                    phandle = <0x0000007e>;
                    endpoint@0 {
                        reg = <0x00000000>;
                        remote-endpoint = <0x0000003d>;
                        linux,phandle = <0x0000003e>;
                        phandle = <0x0000003e>;
                    };
                };
            };
        };
        display-backend@01e60000 {
            compatible = "allwinner,sun5i-a13-display-backend";
            reg = <0x01e60000 0x00000063>;
            clocks = <0x00000002 0x0000001a 0x61686200 0x00000004 0x00000005>;
            clock-names = "ahb", "mod", "ram";
            resets = <0x00000003>;
            status = "okay";
            assigned-clocks = <0x00000003>;
            assigned-clock-rates = <0x11e1a300>;
            linux,phandle = <0x0000007f>;
            phandle = <0x0000007f>;
            ports {
                #address-cells = <0x00000001>;
                #size-cells = <0x00000000>;
                port@0 {
                    #address-cells = <0x00000001>;
                    #size-cells = <0x00000000>;
                    reg = <0x00000000>;
                    linux,phandle = <0x00000080>;
                    phandle = <0x00000080>;
                    endpoint@0 {
                        reg = <0x00000000>;
                        remote-endpoint = <0x0000003e>;
                        linux,phandle = <0x0000003d>;
                        phandle = <0x0000003d>;
                    };
                };
                port@1 {
                    #address-cells = <0x00000001>;
                    #size-cells = <0x00000000>;
                    reg = <0x00000001>;
                    linux,phandle = <0x00000081>;
                    phandle = <0x00000081>;
                    endpoint@0 {
                        reg = <0x00000000>;
                        remote-endpoint = <0x0000003f>;
                        linux,phandle = <0x0000003a>;
                        phandle = <0x0000003a>;
                    };
                };
            };
        };
        tv-encoder@01c0a000 {
            compatible = "allwinner,sun4i-a10-tv-encoder";
            reg = <0x01c0a000 0x00000063>;
            clocks = <0x00000002 0x0000027d>;
            resets = <0x00000004 0x0000006a>;
            status = "okay";
            linux,phandle = <0x00000082>;
            phandle = <0x00000082>;
            port {
                #address-cells = <0x00000001>;
                #size-cells = <0x00000000>;
                endpoint@0 {
                    reg = <0x00000000>;
                    remote-endpoint = <0x00000040>;
                    linux,phandle = <0x0000003b>;
                    phandle = <0x0000003b>;
                };
            };
        };
        gpu@01c40000 {
            compatible = "arm,mali-400", "arm,mali-utgard";
            reg = <0x01c40000 0x00000192>;
            interrupts = <0x00000045 0x00000049 0x49525147 0x52515050 0x49525150>;
            interrupt-names = "IRQGP", "IRQGPMMU", "IRQPP0", "IRQPPMMU0", "IRQPMU";
            clocks = <0x00000002 0x00000008 0x00000003>;
            clock-names = "ahb", "mod";
            resets = <0x00000041>;
            assigned-clocks = <0x00000041>;
            assigned-clock-rates = <0x1298be00>;
            linux,phandle = <0x00000083>;
            phandle = <0x00000083>;
        };
    };
    thermal-zones {
        cpu_thermal {
            polling-delay-passive = <0x000000fa>;
            polling-delay = <0x000003e8>;
            thermal-sensors = <0x00000042>;
            cooling-maps {
                map0 {
                    trip = <0x00000043>;
                    cooling-device = <0x00000044 0x00000002 0x00000001>;
                };
            };
            trips {
                cpu_alert0 {
                    temperature = <0x00014c08>;
                    hysteresis = <0x000007d0>;
                    type = "passive";
                    linux,phandle = <0x00000043>;
                    phandle = <0x00000043>;
                };
                cpu_crit {
                    temperature = <0x000186a0>;
                    hysteresis = <0x000007d0>;
                    type = "critical";
                    linux,phandle = <0x00000084>;
                    phandle = <0x00000084>;
                };
            };
        };
    };
    display-engine {
        compatible = "allwinner,sun5i-a13-display-engine";
        allwinner,pipelines = <0x00000045>;
    };
    ahci-5v {
        compatible = "regulator-fixed";
        pinctrl-names = "default";
        pinctrl-0 = <0x00000046>;
        regulator-name = "ahci-5v";
        regulator-min-microvolt = <0x004c4b40>;
        regulator-max-microvolt = <0x004c4b40>;
        regulator-boot-on;
        enable-active-high;
        gpio = <0x0000002b 0x00000003 0x626c6564 0x000000fd>;
        status = "disabled";
        linux,phandle = <0x00000085>;
        phandle = <0x00000085>;
    };
    usb0-vbus {
        compatible = "regulator-fixed";
        pinctrl-names = "default";
        pinctrl-0 = <0x00000047>;
        regulator-name = "usb0-vbus";
        regulator-min-microvolt = <0x004c4b40>;
        regulator-max-microvolt = <0x004c4b40>;
        enable-active-high;
        gpio = <0x0000002b 0x00000003 0x00000000 0x0000002e>;
        status = "okay";
        vin-supply = <0x0000002e>;
        linux,phandle = <0x0000002d>;
        phandle = <0x0000002d>;
    };
    usb1-vbus {
        compatible = "regulator-fixed";
        pinctrl-names = "default";
        pinctrl-0 = <0x00000048>;
        regulator-name = "usb1-vbus";
        regulator-min-microvolt = <0x004c4b40>;
        regulator-max-microvolt = <0x004c4b40>;
        regulator-boot-on;
        enable-active-high;
        gpio = <0x0000002b 0x00000003 0x626c6564 0x000000fd>;
        status = "disabled";
        linux,phandle = <0x00000086>;
        phandle = <0x00000086>;
    };
    usb2-vbus {
        compatible = "regulator-fixed";
        pinctrl-names = "default";
        pinctrl-0 = <0x00000049>;
        regulator-name = "usb2-vbus";
        regulator-min-microvolt = <0x004c4b40>;
        regulator-max-microvolt = <0x004c4b40>;
        regulator-boot-on;
        enable-active-high;
        gpio = <0x0000002b 0x00000003 0x626c6564 0x000000fd>;
        status = "disabled";
        linux,phandle = <0x00000087>;
        phandle = <0x00000087>;
    };
    vcc3v0 {
        compatible = "regulator-fixed";
        regulator-name = "vcc3v0";
        regulator-min-microvolt = <0x002dc6c0>;
        regulator-max-microvolt = <0x002dc6c0>;
        linux,phandle = <0x00000031>;
        phandle = <0x00000031>;
    };
    vcc3v3 {
        compatible = "regulator-fixed";
        regulator-name = "vcc3v3";
        regulator-min-microvolt = <0x00325aa0>;
        regulator-max-microvolt = <0x00325aa0>;
        linux,phandle = <0x00000088>;
        phandle = <0x00000088>;
    };
    vcc5v0 {
        compatible = "regulator-fixed";
        regulator-name = "vcc5v0";
        regulator-min-microvolt = <0x004c4b40>;
        regulator-max-microvolt = <0x004c4b40>;
        linux,phandle = <0x0000002e>;
        phandle = <0x0000002e>;
    };
    leds {
        compatible = "gpio-leds";
        status {
            label = "chip:white:status";
            gpios = <0x0000004a 0x00000003 0x0000000a>;
            default-state = "on";
            linux,default-trigger = "heartbeat";
            linux,phandle = <0x00000089>;
            phandle = <0x00000089>;
        };
    };
    mmc0_pwrseq {
        compatible = "mmc-pwrseq-simple";
        pinctrl-names = "default";
        pinctrl-0 = <0x0000004b>;
        reset-gpios = <0x0000002b 0x00000003 0x00000003 0x00000002>;
        linux,phandle = <0x00000024>;
        phandle = <0x00000024>;
    };
    onewire {
        compatible = "w1-gpio";
        gpios = <0x0000002b 0x00000003 0x756c7400 0x0000004c>;
        pinctrl-names = "default";
        pinctrl-0 = <0x0000004c>;
    };
    wifi_reg {
        compatible = "coupled-voltage-regulator";
        regulator-name = "vcc-wifi";
        vin0-supply = <0x0000004d>;
        vin1-supply = <0x0000004e>;
        linux,phandle = <0x00000023>;
        phandle = <0x00000023>;
    };
    __symbols__ {
        cpu0 = "/cpus/cpu@0";
        dummy = "/clocks/dummy";
        osc24M = "/clocks/clk@01c20050";
        osc3M = "/clocks/osc3M_clk";
        osc32k = "/clocks/clk@0";
        pll1 = "/clocks/clk@01c20000";
        pll2 = "/clocks/clk@01c20008";
        pll3 = "/clocks/clk@01c20010";
        pll3x2 = "/clocks/pll3x2_clk";
        pll4 = "/clocks/clk@01c20018";
        pll5 = "/clocks/clk@01c20020";
        pll6 = "/clocks/clk@01c20028";
        pll7 = "/clocks/clk@01c20030";
        pll7x2 = "/clocks/pll7x2_clk";
        cpu = "/clocks/cpu@01c20054";
        axi = "/clocks/axi@01c20054";
        ahb = "/clocks/ahb@01c20054";
        apb0 = "/clocks/apb0@01c20054";
        apb1 = "/clocks/clk@01c20058";
        axi_gates = "/clocks/clk@01c2005c";
        nand_clk = "/clocks/clk@01c20080";
        ms_clk = "/clocks/clk@01c20084";
        mmc0_clk = "/clocks/clk@01c20088";
        mmc1_clk = "/clocks/clk@01c2008c";
        mmc2_clk = "/clocks/clk@01c20090";
        ts_clk = "/clocks/clk@01c20098";
        ss_clk = "/clocks/clk@01c2009c";
        spi0_clk = "/clocks/clk@01c200a0";
        spi1_clk = "/clocks/clk@01c200a4";
        spi2_clk = "/clocks/clk@01c200a8";
        ir0_clk = "/clocks/clk@01c200b0";
        usb_clk = "/clocks/clk@01c200cc";
        codec_clk = "/clocks/clk@01c20140";
        mbus_clk = "/clocks/clk@01c2015c";
        ahb_gates = "/clocks/clk@01c20060";
        apb0_gates = "/clocks/clk@01c20068";
        apb1_gates = "/clocks/clk@01c2006c";
        dram_gates = "/clocks/clk@01c20100";
        de_be_clk = "/clocks/clk@01c20104";
        de_fe_clk = "/clocks/clk@01c2010c";
        tcon_ch0_clk = "/clocks/clk@01c20118";
        tcon_ch1_clk = "/clocks/clk@01c2012c";
        mali_clk = "/clocks/clk@01c20154";
        sram_a = "/soc@01c00000/sram-controller@01c00000/sram@00000000";
        sram_d = "/soc@01c00000/sram-controller@01c00000/sram@00010000";
        otg_sram = "/soc@01c00000/sram-controller@01c00000/sram@00010000/sram-section@0000";
        dma = "/soc@01c00000/dma-controller@01c02000";
        nfc = "/soc@01c00000/nand@01c03000";
        spi0 = "/soc@01c00000/spi@01c05000";
        spi1 = "/soc@01c00000/spi@01c06000";
        mmc0 = "/soc@01c00000/mmc@01c0f000";
        mmc1 = "/soc@01c00000/mmc@01c10000";
        mmc2 = "/soc@01c00000/mmc@01c11000";
        usb_otg = "/soc@01c00000/usb@01c13000";
        usbphy = "/soc@01c00000/phy@01c13400";
        ehci0 = "/soc@01c00000/usb@01c14000";
        ohci0 = "/soc@01c00000/usb@01c14400";
        spi2 = "/soc@01c00000/spi@01c17000";
        intc = "/soc@01c00000/interrupt-controller@01c20400";
        pio = "/soc@01c00000/pinctrl@01c20800";
        i2c0_pins_a = "/soc@01c00000/pinctrl@01c20800/i2c0@0";
        i2c1_pins_a = "/soc@01c00000/pinctrl@01c20800/i2c1@0";
        i2c2_pins_a = "/soc@01c00000/pinctrl@01c20800/i2c2@0";
        lcd_rgb565_pins = "/soc@01c00000/pinctrl@01c20800/lcd_rgb565@0";
        mmc0_pins_a = "/soc@01c00000/pinctrl@01c20800/mmc0@0";
        mmc2_pins_a = "/soc@01c00000/pinctrl@01c20800/mmc2@0";
        nand_pins_a = "/soc@01c00000/pinctrl@01c20800/nand_base0@0";
        nand_cs0_pins_a = "/soc@01c00000/pinctrl@01c20800/nand_cs@0";
        nand_cs1_pins_a = "/soc@01c00000/pinctrl@01c20800/nand_cs@1";
        nand_rb0_pins_a = "/soc@01c00000/pinctrl@01c20800/nand_rb@0";
        nand_rb1_pins_a = "/soc@01c00000/pinctrl@01c20800/nand_rb@1";
        spi2_pins_a = "/soc@01c00000/pinctrl@01c20800/spi2@0";
        spi2_cs0_pins_a = "/soc@01c00000/pinctrl@01c20800/spi2-cs0@0";
        uart3_pins_a = "/soc@01c00000/pinctrl@01c20800/uart3@0";
        uart3_pins_cts_rts_a = "/soc@01c00000/pinctrl@01c20800/uart3-cts-rts@0";
        pwm0_pins = "/soc@01c00000/pinctrl@01c20800/pwm0";
        lcd_rgb666_pins = "/soc@01c00000/pinctrl@01c20800/lcd_rgb666@0";
        uart1_pins_a = "/soc@01c00000/pinctrl@01c20800/uart1@0";
        uart1_pins_b = "/soc@01c00000/pinctrl@01c20800/uart1@1";
        ahci_pwr_pin_a = "/soc@01c00000/pinctrl@01c20800/ahci_pwr_pin@0";
        usb0_vbus_pin_a = "/soc@01c00000/pinctrl@01c20800/usb0_vbus_pin@0";
        usb1_vbus_pin_a = "/soc@01c00000/pinctrl@01c20800/usb1_vbus_pin@0";
        usb2_vbus_pin_a = "/soc@01c00000/pinctrl@01c20800/usb2_vbus_pin@0";
        chip_vbus_pin = "/soc@01c00000/pinctrl@01c20800/chip_vbus_pin@0";
        chip_wifi_reg_on_pin = "/soc@01c00000/pinctrl@01c20800/chip_wifi_reg_on_pin@0";
        chip_id_det_pin = "/soc@01c00000/pinctrl@01c20800/chip_id_det_pin@0";
        chip_w1_pin = "/soc@01c00000/pinctrl@01c20800/chip_w1_pin@0";
        wdt = "/soc@01c00000/watchdog@01c20c90";
        lradc = "/soc@01c00000/lradc@01c22800";
        codec = "/soc@01c00000/codec@01c22c00";
        sid = "/soc@01c00000/eeprom@01c23800";
        rtp = "/soc@01c00000/rtp@01c25000";
        uart1 = "/soc@01c00000/serial@01c28400";
        uart3 = "/soc@01c00000/serial@01c28c00";
        i2c0 = "/soc@01c00000/i2c@01c2ac00";
        axp209 = "/soc@01c00000/i2c@01c2ac00/pmic@34";
        axp_gpio = "/soc@01c00000/i2c@01c2ac00/pmic@34/gpio";
        reg_dcdc2 = "/soc@01c00000/i2c@01c2ac00/pmic@34/regulators/dcdc2";
        reg_dcdc3 = "/soc@01c00000/i2c@01c2ac00/pmic@34/regulators/dcdc3";
        reg_ldo1 = "/soc@01c00000/i2c@01c2ac00/pmic@34/regulators/ldo1";
        reg_ldo2 = "/soc@01c00000/i2c@01c2ac00/pmic@34/regulators/ldo2";
        reg_ldo3 = "/soc@01c00000/i2c@01c2ac00/pmic@34/regulators/ldo3";
        reg_ldo4 = "/soc@01c00000/i2c@01c2ac00/pmic@34/regulators/ldo4";
        reg_ldo5 = "/soc@01c00000/i2c@01c2ac00/pmic@34/regulators/ldo5";
        usb_power_supply = "/soc@01c00000/i2c@01c2ac00/pmic@34/usb_power_supply";
        i2c1 = "/soc@01c00000/i2c@01c2b000";
        i2c2 = "/soc@01c00000/i2c@01c2b400";
        xio = "/soc@01c00000/i2c@01c2b400/gpio@38";
        tcon0 = "/soc@01c00000/lcd-controller@01c0c000";
        tcon0_in = "/soc@01c00000/lcd-controller@01c0c000/ports/port@0";
        tcon0_in_be0 = "/soc@01c00000/lcd-controller@01c0c000/ports/port@0/endpoint@0";
        tcon0_out = "/soc@01c00000/lcd-controller@01c0c000/ports/port@1";
        tcon0_out_tve0 = "/soc@01c00000/lcd-controller@01c0c000/ports/port@1/endpoint@1";
        pwm = "/soc@01c00000/pwm@01c20e00";
        fe0 = "/soc@01c00000/display-frontend@01e00000";
        fe0_out = "/soc@01c00000/display-frontend@01e00000/ports/port@1";
        fe0_out_be0 = "/soc@01c00000/display-frontend@01e00000/ports/port@1/endpoint@0";
        be0 = "/soc@01c00000/display-backend@01e60000";
        be0_in = "/soc@01c00000/display-backend@01e60000/ports/port@0";
        be0_in_fe0 = "/soc@01c00000/display-backend@01e60000/ports/port@0/endpoint@0";
        be0_out = "/soc@01c00000/display-backend@01e60000/ports/port@1";
        be0_out_tcon0 = "/soc@01c00000/display-backend@01e60000/ports/port@1/endpoint@0";
        tve0 = "/soc@01c00000/tv-encoder@01c0a000";
        tve0_in_tcon0 = "/soc@01c00000/tv-encoder@01c0a000/port/endpoint@0";
        mali = "/soc@01c00000/gpu@01c40000";
        cpu_alert0 = "/thermal-zones/cpu_thermal/trips/cpu_alert0";
        cpu_crit = "/thermal-zones/cpu_thermal/trips/cpu_crit";
        reg_ahci_5v = "/ahci-5v";
        reg_usb0_vbus = "/usb0-vbus";
        reg_usb1_vbus = "/usb1-vbus";
        reg_usb2_vbus = "/usb2-vbus";
        reg_vcc3v0 = "/vcc3v0";
        reg_vcc3v3 = "/vcc3v3";
        reg_vcc5v0 = "/vcc5v0";
        leds_status = "/leds/status";
        mmc0_pwrseq = "/mmc0_pwrseq";
        vcc_wifi = "/wifi_reg";
    };
    __local_fixups__ {
        interrupt-parent = <0x00000000>;
        chosen {
            framebuffer@0 {
                clocks = <0x00000000 0x00000018 0x65627566 0x00000018 0x00000010>;
            };
            framebuffer@1 {
                clocks = <0x00000000 0x0000001c 0x00000001 0x63707540 0x00000063 0x000000f2>;
            };
        };
        cpus {
            cpu@0 {
                clocks = <0x00000000>;
                cpu-supply = <0x00000000>;
            };
        };
        clocks {
            osc3M_clk {
                clocks = <0x00000000>;
            };
            clk@01c20000 {
                clocks = <0x00000000>;
            };
            clk@01c20008 {
                clocks = <0x00000000>;
            };
            clk@01c20010 {
                clocks = <0x00000000>;
            };
            pll3x2_clk {
                clocks = <0x00000000>;
            };
            clk@01c20018 {
                clocks = <0x00000000>;
            };
            clk@01c20020 {
                clocks = <0x00000000>;
            };
            clk@01c20028 {
                clocks = <0x00000000>;
            };
            clk@01c20030 {
                clocks = <0x00000000>;
            };
            pll7x2_clk {
                clocks = <0x00000000>;
            };
            cpu@01c20054 {
                clocks = <0x00000000 0x00000002 0x30303534 0x00000063>;
            };
            axi@01c20054 {
                clocks = <0x00000000>;
            };
            ahb@01c20054 {
                clocks = <0x00000000 0x00000004 0x00000004>;
                assigned-clocks = <0x00000000>;
                assigned-clock-parents = <0x00000000>;
            };
            apb0@01c20054 {
                clocks = <0x00000000>;
            };
            clk@01c20058 {
                clocks = <0x00000000 0x00000001 0x00000000>;
            };
            clk@01c2005c {
                clocks = <0x00000000>;
            };
            clk@01c20080 {
                clocks = <0x00000000 0x00000001 0x00000000>;
            };
            clk@01c20084 {
                clocks = <0x00000000 0x00000001 0x00000000>;
            };
            clk@01c20088 {
                clocks = <0x00000000 0x00000001 0x00000000>;
            };
            clk@01c2008c {
                clocks = <0x00000000 0x00000001 0x00000000>;
            };
            clk@01c20090 {
                clocks = <0x00000000 0x00000001 0x00000000>;
            };
            clk@01c20098 {
                clocks = <0x00000000 0x00000001 0x00000000>;
            };
            clk@01c2009c {
                clocks = <0x00000000 0x00000001 0x00000000>;
            };
            clk@01c200a0 {
                clocks = <0x00000000 0x00000001 0x00000000>;
            };
            clk@01c200a4 {
                clocks = <0x00000000 0x00000001 0x00000000>;
            };
            clk@01c200a8 {
                clocks = <0x00000000 0x00000001 0x00000000>;
            };
            clk@01c200b0 {
                clocks = <0x00000000 0x00000001 0x00000000>;
            };
            clk@01c200cc {
                clocks = <0x00000000>;
            };
            clk@01c20140 {
                clocks = <0x00000000>;
            };
            clk@01c2015c {
                clocks = <0x00000000 0x00000001 0x00000000>;
            };
            clk@01c20060 {
                clocks = <0x00000000>;
            };
            clk@01c20068 {
                clocks = <0x00000000>;
            };
            clk@01c2006c {
                clocks = <0x00000000>;
            };
            clk@01c20100 {
                clocks = <0x00000000>;
            };
            clk@01c20104 {
                clocks = <0x00000000 0x00000001 0x00000000>;
            };
            clk@01c2010c {
                clocks = <0x00000000 0x00000001 0x00000000>;
            };
            clk@01c20118 {
                clocks = <0x00000000 0x00000002 0x30313263 0x00000063>;
            };
            clk@01c2012c {
                clocks = <0x00000000 0x00000002 0x30313534 0x00000063>;
            };
            clk@01c20154 {
                clocks = <0x00000000 0x00000014 0x736f6340 0x00000001 0x65724030>;
            };
        };
        soc@01c00000 {
            dma-controller@01c02000 {
                clocks = <0x00000000>;
            };
            nand@01c03000 {
                clocks = <0x00000000 0x000001c2>;
                pinctrl-0 = <0x00000000 0x00000004 0x00000001>;
                dmas = <0x00000000>;
            };
            spi@01c05000 {
                clocks = <0x00000000 0x000001cc>;
                dmas = <0x00000000 0x73706940>;
            };
            spi@01c06000 {
                clocks = <0x00000000 0x000001cc>;
                dmas = <0x00000000 0x6d6d6340>;
            };
            mmc@01c0f000 {
                clocks = <0x00000000 0x00000003 0x00000003 0x00000003>;
                pinctrl-0 = <0x00000000>;
                vmmc-supply = <0x00000000>;
                mmc-pwrseq = <0x00000000>;
            };
            mmc@01c10000 {
                clocks = <0x00000000 0x00000002 0x31303030 0x00000063>;
            };
            mmc@01c11000 {
                clocks = <0x00000000 0x00000002 0x33303030 0x00000063>;
            };
            usb@01c13000 {
                clocks = <0x00000000>;
                phys = <0x00000000>;
                extcon = <0x00000000>;
                allwinner,sram = <0x00000000>;
            };
            phy@01c13400 {
                clocks = <0x00000000>;
                resets = <0x00000000 0x000001c2>;
                pinctrl-0 = <0x00000000>;
                usb0_id_det-gpio = <0x00000000>;
                usb0_vbus_power-supply = <0x00000000>;
                usb0_vbus-supply = <0x00000000>;
                usb1_vbus-supply = <0x00000000>;
            };
            usb@01c14000 {
                clocks = <0x00000000>;
                phys = <0x00000000>;
            };
            usb@01c14400 {
                clocks = <0x00000000 0x0000023b>;
                phys = <0x00000000>;
            };
            spi@01c17000 {
                clocks = <0x00000000 0x000001cc>;
                dmas = <0x00000000 0x70696e63>;
            };
            pinctrl@01c20800 {
                clocks = <0x00000000>;
            };
            timer@01c20c00 {
                clocks = <0x00000000>;
            };
            lradc@01c22800 {
                vref-supply = <0x00000000>;
            };
            codec@01c22c00 {
                clocks = <0x00000000 0x000001cc>;
                dmas = <0x00000000 0x73657269>;
            };
            serial@01c28400 {
                clocks = <0x00000000>;
                pinctrl-0 = <0x00000000>;
            };
            serial@01c28c00 {
                clocks = <0x00000000>;
                pinctrl-0 = <0x00000000 0x69326340>;
            };
            i2c@01c2ac00 {
                clocks = <0x00000000>;
                pinctrl-0 = <0x00000000>;
            };
            i2c@01c2b000 {
                clocks = <0x00000000>;
                pinctrl-0 = <0x00000000>;
            };
            i2c@01c2b400 {
                clocks = <0x00000000>;
                pinctrl-0 = <0x00000000>;
                gpio@38 {
                    interrupt-parent = <0x00000000>;
                };
            };
            timer@01c60000 {
                clocks = <0x00000000>;
            };
            lcd-controller@01c0c000 {
                resets = <0x00000000>;
                clocks = <0x00000000 0x706f7274 0x40300000>;
                ports {
                    port@0 {
                        endpoint@0 {
                            remote-endpoint = <0x00000000>;
                        };
                    };
                    port@1 {
                        endpoint@1 {
                            remote-endpoint = <0x00000000>;
                        };
                    };
                };
            };
            pwm@01c20e00 {
                clocks = <0x00000000>;
            };
            display-frontend@01e00000 {
                clocks = <0x00000000 0x00000004 0x706f7274>;
                resets = <0x00000000>;
                ports {
                    port@1 {
                        endpoint@0 {
                            remote-endpoint = <0x00000000>;
                        };
                    };
                };
            };
            display-backend@01e60000 {
                clocks = <0x00000000 0x00000004 0x00000004>;
                resets = <0x00000000>;
                assigned-clocks = <0x00000000>;
                ports {
                    port@0 {
                        endpoint@0 {
                            remote-endpoint = <0x00000000>;
                        };
                    };
                    port@1 {
                        endpoint@0 {
                            remote-endpoint = <0x00000000>;
                        };
                    };
                };
            };
            tv-encoder@01c0a000 {
                clocks = <0x00000000>;
                resets = <0x00000000>;
                port {
                    endpoint@0 {
                        remote-endpoint = <0x00000000>;
                    };
                };
            };
            gpu@01c40000 {
                clocks = <0x00000000 0x0000027d>;
                resets = <0x00000000>;
                assigned-clocks = <0x00000000>;
            };
        };
        thermal-zones {
            cpu_thermal {
                thermal-sensors = <0x00000000>;
                cooling-maps {
                    map0 {
                        trip = <0x00000000>;
                        cooling-device = <0x00000000>;
                    };
                };
            };
        };
        display-engine {
            allwinner,pipelines = <0x00000000>;
        };
        ahci-5v {
            pinctrl-0 = <0x00000000>;
            gpio = <0x00000000>;
        };
        usb0-vbus {
            pinctrl-0 = <0x00000000>;
            gpio = <0x00000000>;
            vin-supply = <0x00000000>;
        };
        usb1-vbus {
            pinctrl-0 = <0x00000000>;
            gpio = <0x00000000>;
        };
        usb2-vbus {
            pinctrl-0 = <0x00000000>;
            gpio = <0x00000000>;
        };
        leds {
            status {
                gpios = <0x00000000>;
            };
        };
        mmc0_pwrseq {
            pinctrl-0 = <0x00000000>;
            reset-gpios = <0x00000000>;
        };
        onewire {
            gpios = <0x00000000>;
            pinctrl-0 = <0x00000000>;
        };
        wifi_reg {
            vin0-supply = <0x00000000>;
            vin1-supply = <0x00000000>;
        };
    };
};
